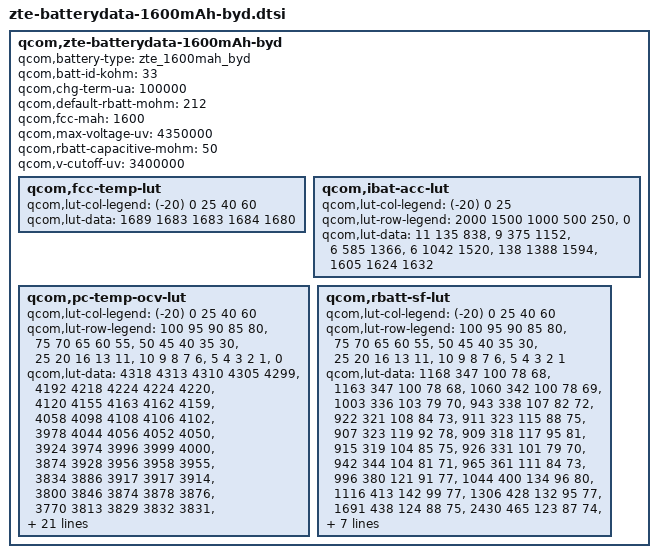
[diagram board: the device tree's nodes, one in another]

qcom,zte-batterydata-1600mAh-byd {
	qcom,battery-type = "zte_1600mah_byd";
	qcom,batt-id-kohm = <33>;
	qcom,chg-term-ua = <100000>;
	qcom,default-rbatt-mohm = <212>;
	qcom,fcc-mah = <1600>;
	qcom,max-voltage-uv = <4350000>;
	qcom,rbatt-capacitive-mohm = <50>;
	qcom,v-cutoff-uv = <3400000>;

	qcom,fcc-temp-lut {
		qcom,lut-col-legend = <(-20) 0 25 40 60>;
		qcom,lut-data = <1689 1683 1683 1684 1680>;
	};

	qcom,ibat-acc-lut {
		qcom,lut-col-legend = <(-20) 0 25>;
		qcom,lut-row-legend = <2000 1500 1000 500 250>,
					<0>;
		qcom,lut-data = <11 135 838>,
				<9 375 1152>,
				<6 585 1366>,
				<6 1042 1520>,
				<138 1388 1594>,
				<1605 1624 1632>;
	};

	qcom,pc-temp-ocv-lut {
		qcom,lut-col-legend = <(-20) 0 25 40 60>;
		qcom,lut-row-legend = <100 95 90 85 80>,
					<75 70 65 60 55>,
					<50 45 40 35 30>,
					<25 20 16 13 11>,
					<10 9 8 7 6>,
					<5 4 3 2 1>,
					<0>;
		qcom,lut-data = <4318 4313 4310 4305 4299>,
				<4192 4218 4224 4224 4220>,
				<4120 4155 4163 4162 4159>,
				<4058 4098 4108 4106 4102>,
				<3978 4044 4056 4052 4050>,
				<3924 3974 3996 3999 4000>,
				<3874 3928 3956 3958 3955>,
				<3834 3886 3917 3917 3914>,
				<3800 3846 3874 3878 3876>,
				<3770 3813 3829 3832 3831>,
				<3744 3790 3800 3800 3799>,
				<3722 3773 3783 3782 3780>,
				<3700 3759 3776 3774 3769>,
				<3678 3745 3772 3770 3764>,
				<3658 3726 3765 3762 3756>,
				<3635 3690 3740 3738 3728>,
				<3609 3642 3681 3684 3678>,
				<3582 3598 3619 3621 3618>,
				<3554 3560 3571 3572 3570>,
				<3530 3538 3542 3544 3543>,
				<3515 3528 3532 3536 3534>,
				<3499 3518 3524 3528 3526>,
				<3481 3507 3516 3520 3518>,
				<3460 3496 3507 3510 3509>,
				<3436 3483 3496 3499 3495>,
				<3406 3463 3476 3476 3466>,
				<3364 3428 3436 3430 3419>,
				<3308 3377 3378 3370 3359>,
				<3234 3302 3302 3296 3286>,
				<3138 3202 3197 3198 3178>,
				<3000 3000 3000 3000 3000>;
	};

	qcom,rbatt-sf-lut {
		qcom,lut-col-legend = <(-20) 0 25 40 60>;
		qcom,lut-row-legend = <100 95 90 85 80>,
					<75 70 65 60 55>,
					<50 45 40 35 30>,
					<25 20 16 13 11>,
					<10 9 8 7 6>,
					<5 4 3 2 1>;
		qcom,lut-data = <1168 347 100 78 68>,
				<1163 347 100 78 68>,
				<1060 342 100 78 69>,
				<1003 336 103 79 70>,
				<943 338 107 82 72>,
				<922 321 108 84 73>,
				<911 323 115 88 75>,
				<907 323 119 92 78>,
				<909 318 117 95 81>,
				<915 319 104 85 75>,
				<926 331 101 79 70>,
				<942 344 104 81 71>,
				<965 361 111 84 73>,
				<996 380 121 91 77>,
				<1044 400 134 96 80>,
				<1116 413 142 99 77>,
				<1306 428 132 95 77>,
				<1691 438 124 88 75>,
				<2430 465 123 87 74>,
				<3782 512 124 85 72>,
				<5060 555 126 86 73>,
				<6979 633 130 88 75>,
				<9962 777 136 91 76>,
				<14519 1075 143 94 77>,
				<21298 1511 153 97 78>,
				<31648 2201 163 98 76>,
				<47254 3373 173 98 77>,
				<69651 5213 204 103 79>,
				<100622 8558 279 115 85>,
				<150352 13535 542 138 99>;
	};
};
